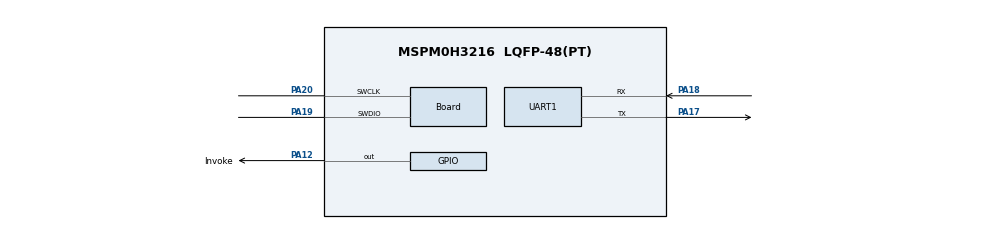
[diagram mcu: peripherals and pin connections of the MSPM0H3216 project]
//@cliArgs --device "MSPM0H321X" --package "LQFP-48(PT)" --part "Default"
//@v2CliArgs --device "MSPM0H3216" --package "LQFP-48(PT)"
// @cliArgs --board /ti/boards/LP_MSPM0H3216 --rtos nortos

/**
 * Import the modules used in this configuration.
 */
const GPIO          = scripting.addModule("/ti/driverlib/GPIO", {}, false);
const GPIO1         = GPIO.addInstance();
const GPIO2         = GPIO.addInstance();
const GPIO3         = GPIO.addInstance();
const UART          = scripting.addModule("/ti/driverlib/UART", {}, false);
const UART1         = UART.addInstance();
const ProjectConfig = scripting.addModule("/ti/project_config/ProjectConfig");

/**
 * Write custom configuration values to the imported modules.
 */
GPIO1.$name                              = "GPIO_Button";
GPIO1.associatedPins[0].$name            = "PIN_0";
GPIO1.associatedPins[0].assignedPort     = "PORTA";
GPIO1.associatedPins[0].direction        = "INPUT";
GPIO1.associatedPins[0].internalResistor = "PULL_UP";
GPIO1.associatedPins[0].assignedPin      = "14";

const Board                       = scripting.addModule("/ti/driverlib/Board", {}, false);
Board.configureUnused             = true;
Board.peripheral.$assign          = "DEBUGSS";
Board.peripheral.swclkPin.$assign = "PA20";
Board.peripheral.swdioPin.$assign = "PA19";

GPIO2.$name                          = "GPIO_BSL";
GPIO2.associatedPins.create(2);
GPIO2.associatedPins[0].$name        = "NRST";
GPIO2.associatedPins[0].assignedPort = "PORTA";
GPIO2.associatedPins[0].assignedPin  = "13";
GPIO2.associatedPins[1].$name        = "Invoke";
GPIO2.associatedPins[1].assignedPort = "PORTA";
GPIO2.associatedPins[1].assignedPin  = "12";
GPIO2.associatedPins[1].pin.$assign  = "PA12";

GPIO3.$name                          = "GPIO_LED";
GPIO3.associatedPins[0].assignedPort = "PORTA";
GPIO3.associatedPins[0].$name        = "Error";
GPIO3.associatedPins[0].assignedPin  = "0";
GPIO3.associatedPins[0].initialValue = "SET";

const SYSCTL       = scripting.addModule("/ti/driverlib/SYSCTL", {}, false);
SYSCTL.powerPolicy = "STANDBY0";
SYSCTL.clockTreeEn = true;

UART1.$name                    = "UART_0";
UART1.enabledInterrupts        = ["RX"];
UART1.peripheral.$assign       = "UART1";
UART1.peripheral.rxPin.$assign = "PA18";
UART1.peripheral.txPin.$assign = "PA17";

ProjectConfig.migrationCondition = true;
